# ESP32 register map
Vendor: ESPRESSIF SYSTEMS (SHANGHAI) CO., LTD.; Series: ESP32 Series; File version: 17
CPU: Xtensa LX6 r0p0, little endian, no MPU, FPU, 0 interrupt priority bits
Address unit: 32 bits
Registers are 32-bit, read-write, reset 0x0 unless marked. A register's access mark holds for its fields unless they carry their own. Offsets are from the block's base; [hi:lo] are bit positions; {n}, {i} and the like mark numbered series.

## UHCI0 — Universal Host Controller Interface 0
Base 0x3FF54000
Same registers: UHCI1 0x3FF4C000
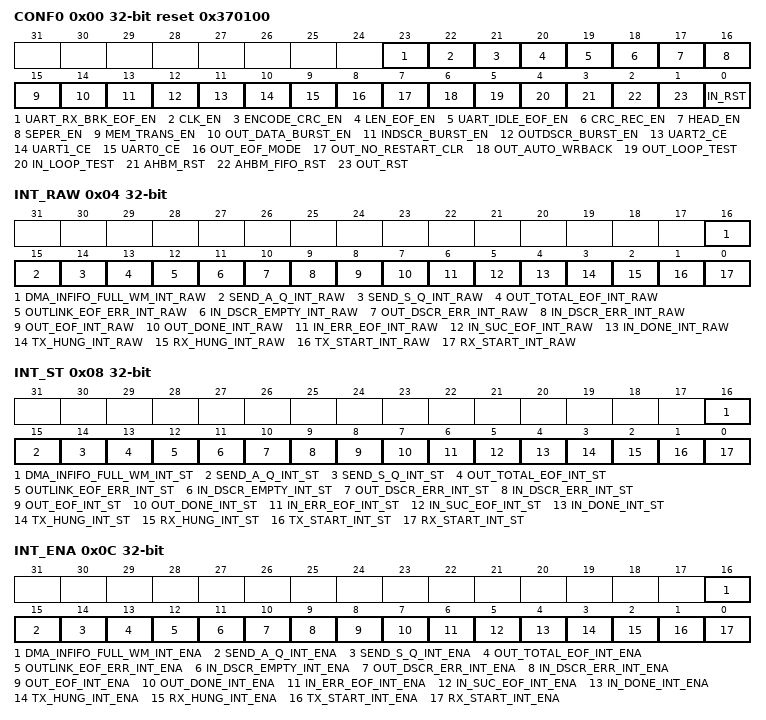
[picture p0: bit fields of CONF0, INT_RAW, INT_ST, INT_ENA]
0x00 CONF0 reset 0x370100
  [23] UART_RX_BRK_EOF_EN — Set this bit to enable to use brk char as the end of a data frame.
  [22] CLK_EN — Set this bit to enable clock-gating for read or write registers.
  [21] ENCODE_CRC_EN — Set this bit to enable crc calculation for data frame when bit6 in the head packet is 1.
  [20] LEN_EOF_EN — Set this bit to enable to use packet_len in packet head when the received data is equal to packet_len this means the end of a data frame.
  [19] UART_IDLE_EOF_EN — Set this bit to enable to use idle time when the idle time after data frame is satisfied this means the end of a data frame.
  [18] CRC_REC_EN — Set this bit to enable receiver''s ability of crc calculation when crc_en bit in head packet is 1 then there will be crc bytes after data_frame
  [17] HEAD_EN — Set this bit to enable to use head packet before the data frame.
  [16] SEPER_EN — Set this bit to use special char to separate the data frame.
  [15] MEM_TRANS_EN
  [14] OUT_DATA_BURST_EN — Set this bit to enable DMA burst MODE
  [13] INDSCR_BURST_EN — Set this bit to enable DMA out links to use burst mode.
  [12] OUTDSCR_BURST_EN — Set this bit to enable DMA in links to use burst mode.
  [11] UART2_CE — Set this bit to use UART2 to transmit or receive data.
  [10] UART1_CE — Set this bit to use UART1 to transmit or receive data.
  [9] UART0_CE — Set this bit to use UART to transmit or receive data.
  [8] OUT_EOF_MODE — Set this bit to produce eof after DMA pops all data clear this bit to produce eof after DMA pushes all data
  [7] OUT_NO_RESTART_CLR — don't use
  [6] OUT_AUTO_WRBACK — when in link's length is 0 go on to use the next in link automatically.
  [5] OUT_LOOP_TEST — Set this bit to enable loop test for out links.
  [4] IN_LOOP_TEST — Set this bit to enable loop test for in links.
  [3] AHBM_RST — Set this bit to reset dma ahb interface.
  [2] AHBM_FIFO_RST — Set this bit to reset dma ahb fifo.
  [1] OUT_RST — Set this bit to reset out link operations.
  [0] IN_RST — Set this bit to reset in link operations.
0x04 INT_RAW ro
  [16] DMA_INFIFO_FULL_WM_INT_RAW
  [15] SEND_A_Q_INT_RAW — When use always_send registers to send a series of short packets it will produce this interrupt when dma has send the short packet.
  [14] SEND_S_Q_INT_RAW — When use single send registers to send a short packets it will produce this interrupt when dma has send the short packet.
  [13] OUT_TOTAL_EOF_INT_RAW — When all data have been send it will produce uhci_out_total_eof_int interrupt.
  [12] OUTLINK_EOF_ERR_INT_RAW — when there are some errors about eof in outlink descriptor it will produce uhci_outlink_eof_err_int interrupt.
  [11] IN_DSCR_EMPTY_INT_RAW — when there are not enough in links for DMA it will produce uhci_in_dscr_err_int interrupt.
  [10] OUT_DSCR_ERR_INT_RAW — when there are some errors about the in link descriptor it will produce uhci_out_dscr_err_int interrupt.
  [9] IN_DSCR_ERR_INT_RAW — when there are some errors about the out link descriptor it will produce uhci_in_dscr_err_int interrupt.
  [8] OUT_EOF_INT_RAW — when the current descriptor's eof bit is 1 it will produce uhci_out_eof_int interrupt.
  [7] OUT_DONE_INT_RAW — when a out link descriptor is completed it will produce uhci_out_done_int interrupt.
  [6] IN_ERR_EOF_INT_RAW — when there are some errors about eof in in link descriptor it will produce uhci_in_err_eof_int interrupt.
  [5] IN_SUC_EOF_INT_RAW — when a data packet has been received it will produce uhci_in_suc_eof_int interrupt.
  [4] IN_DONE_INT_RAW — when a in link descriptor has been completed it will produce uhci_in_done_int interrupt.
  [3] TX_HUNG_INT_RAW — when DMA takes a lot of time to read a data from RAM it will produce uhci_tx_hung_int interrupt.
  [2] RX_HUNG_INT_RAW — when DMA takes a lot of time to receive a data it will produce uhci_rx_hung_int interrupt.
  [1] TX_START_INT_RAW — when DMA detects a separator char it will produce uhci_tx_start_int interrupt.
  [0] RX_START_INT_RAW — when a separator char has been send it will produce uhci_rx_start_int interrupt.
0x08 INT_ST ro
  [16] DMA_INFIFO_FULL_WM_INT_ST, [15] SEND_A_Q_INT_ST, [14] SEND_S_Q_INT_ST, [13] OUT_TOTAL_EOF_INT_ST, [12] OUTLINK_EOF_ERR_INT_ST, [11] IN_DSCR_EMPTY_INT_ST, [10] OUT_DSCR_ERR_INT_ST, [9] IN_DSCR_ERR_INT_ST, [8] OUT_EOF_INT_ST, [7] OUT_DONE_INT_ST, [6] IN_ERR_EOF_INT_ST, [5] IN_SUC_EOF_INT_ST, [4] IN_DONE_INT_ST, [3] TX_HUNG_INT_ST, [2] RX_HUNG_INT_ST, [1] TX_START_INT_ST, [0] RX_START_INT_ST
0x0C INT_ENA
  [16] DMA_INFIFO_FULL_WM_INT_ENA, [15] SEND_A_Q_INT_ENA, [14] SEND_S_Q_INT_ENA, [13] OUT_TOTAL_EOF_INT_ENA, [12] OUTLINK_EOF_ERR_INT_ENA, [11] IN_DSCR_EMPTY_INT_ENA, [10] OUT_DSCR_ERR_INT_ENA, [9] IN_DSCR_ERR_INT_ENA, [8] OUT_EOF_INT_ENA, [7] OUT_DONE_INT_ENA, [6] IN_ERR_EOF_INT_ENA, [5] IN_SUC_EOF_INT_ENA, [4] IN_DONE_INT_ENA, [3] TX_HUNG_INT_ENA, [2] RX_HUNG_INT_ENA, [1] TX_START_INT_ENA, [0] RX_START_INT_ENA
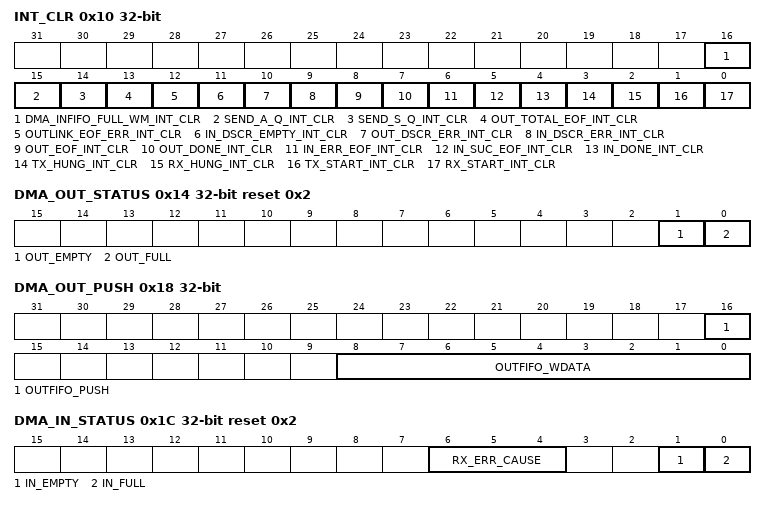
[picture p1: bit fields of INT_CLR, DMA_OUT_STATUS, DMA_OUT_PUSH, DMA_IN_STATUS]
0x10 INT_CLR wo
  [16] DMA_INFIFO_FULL_WM_INT_CLR, [15] SEND_A_Q_INT_CLR, [14] SEND_S_Q_INT_CLR, [13] OUT_TOTAL_EOF_INT_CLR, [12] OUTLINK_EOF_ERR_INT_CLR, [11] IN_DSCR_EMPTY_INT_CLR, [10] OUT_DSCR_ERR_INT_CLR, [9] IN_DSCR_ERR_INT_CLR, [8] OUT_EOF_INT_CLR, [7] OUT_DONE_INT_CLR, [6] IN_ERR_EOF_INT_CLR, [5] IN_SUC_EOF_INT_CLR, [4] IN_DONE_INT_CLR, [3] TX_HUNG_INT_CLR, [2] RX_HUNG_INT_CLR, [1] TX_START_INT_CLR, [0] RX_START_INT_CLR
0x14 DMA_OUT_STATUS ro reset 0x2
  [1] OUT_EMPTY — 1:DMA in link descriptor's fifo is empty.
  [0] OUT_FULL — 1:DMA out link descriptor's fifo is full.
0x18 DMA_OUT_PUSH
  [16] OUTFIFO_PUSH — Set this bit to push data in out link descriptor's fifo.
  [8:0] OUTFIFO_WDATA — This is the data need to be pushed into out link descriptor's fifo.
0x1C DMA_IN_STATUS ro reset 0x2
  [6:4] RX_ERR_CAUSE — This register stores the errors caused in out link descriptor's data packet.
  [1] IN_EMPTY
  [0] IN_FULL
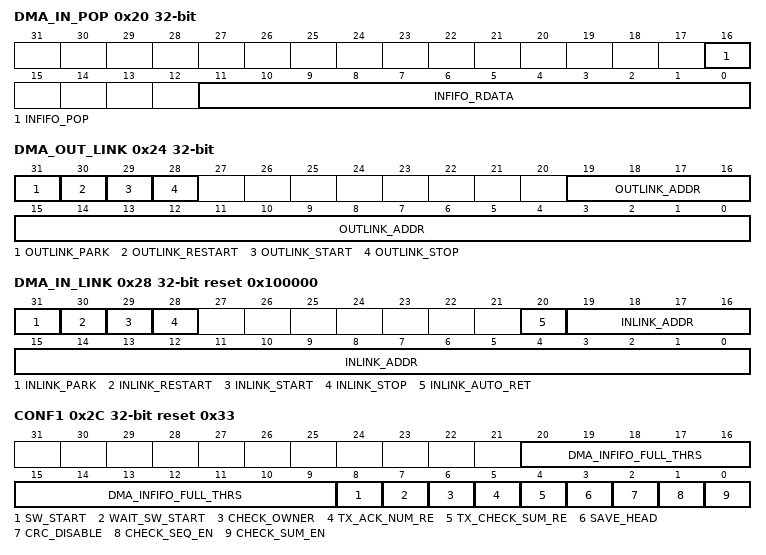
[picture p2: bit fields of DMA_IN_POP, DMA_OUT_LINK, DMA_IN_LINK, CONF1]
0x20 DMA_IN_POP access per field
  [16] INFIFO_POP rw — Set this bit to pop data in in link descriptor's fifo.
  [11:0] INFIFO_RDATA ro — This register stores the data pop from in link descriptor's fifo.
0x24 DMA_OUT_LINK access per field
  [31] OUTLINK_PARK ro — 1£º the out link descriptor's fsm is in idle state. 0:the out link descriptor's fsm is working.
  [30] OUTLINK_RESTART rw — Set this bit to mount on new out link descriptors
  [29] OUTLINK_START rw — Set this bit to start dealing with the out link descriptors.
  [28] OUTLINK_STOP rw — Set this bit to stop dealing with the out link descriptors.
  [19:0] OUTLINK_ADDR rw — This register stores the least 20 bits of the first out link descriptor's address.
0x28 DMA_IN_LINK access per field reset 0x100000
  [31] INLINK_PARK ro — 1:the in link descriptor's fsm is in idle state. 0:the in link descriptor's fsm is working
  [30] INLINK_RESTART rw — Set this bit to mount on new in link descriptors
  [29] INLINK_START rw — Set this bit to start dealing with the in link descriptors.
  [28] INLINK_STOP rw — Set this bit to stop dealing with the in link descriptors.
  [20] INLINK_AUTO_RET rw — 1:when a packet is wrong in link descriptor returns to the descriptor which is lately used.
  [19:0] INLINK_ADDR rw — This register stores the least 20 bits of the first in link descriptor's address.
0x2C CONF1 reset 0x33
  [20:9] DMA_INFIFO_FULL_THRS — when data amount in link descriptor's fifo is more than this register value it will produce uhci_dma_infifo_full_wm_int interrupt.
  [8] SW_START — Set this bit to start inserting the packet header.
  [7] WAIT_SW_START — Set this bit to enable software way to add packet header.
  [6] CHECK_OWNER — Set this bit to check the owner bit in link descriptor.
  [5] TX_ACK_NUM_RE — Set this bit to enable hardware replace ack num in packet header automatically.
  [4] TX_CHECK_SUM_RE — Set this bit to enable hardware replace check_sum in packet header automatically.
  [3] SAVE_HEAD — Set this bit to save packet header .
  [2] CRC_DISABLE — Set this bit to disable crc calculation.
  [1] CHECK_SEQ_EN — Set this bit to enable decoder to check seq num in packet header.
  [0] CHECK_SUM_EN — Set this bit to enable decoder to check check_sum in packet header.
0x30 STATE0 ro
0x34 STATE1 ro
0x38 DMA_OUT_EOF_DES_ADDR ro
  [31:0] OUT_EOF_DES_ADDR — This register stores the address of out link descriptoir when eof bit in this descriptor is 1.
0x3C DMA_IN_SUC_EOF_DES_ADDR ro
  [31:0] IN_SUC_EOF_DES_ADDR — This register stores the address of in link descriptor when eof bit in this descriptor is 1.
0x40 DMA_IN_ERR_EOF_DES_ADDR ro
  [31:0] IN_ERR_EOF_DES_ADDR — This register stores the address of in link descriptor when there are some errors in this descriptor.
0x44 DMA_OUT_EOF_BFR_DES_ADDR ro
  [31:0] OUT_EOF_BFR_DES_ADDR — This register stores the address of out link descriptor when there are some errors in this descriptor.
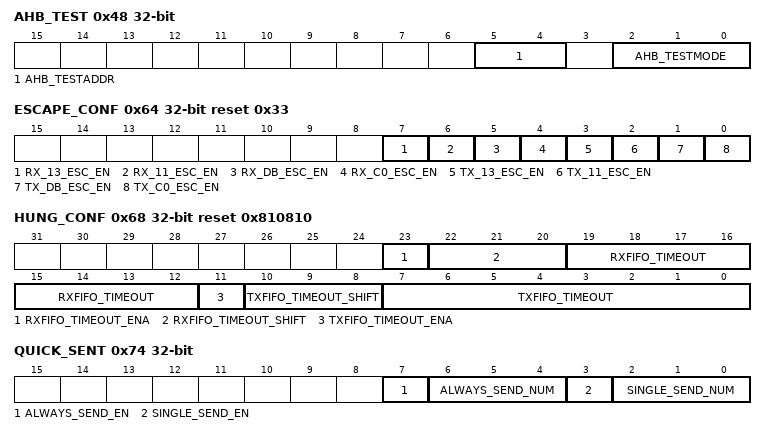
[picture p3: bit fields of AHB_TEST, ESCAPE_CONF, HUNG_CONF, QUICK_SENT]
0x48 AHB_TEST
  [5:4] AHB_TESTADDR — The two bits represent ahb bus address bit[20:19]
  [2:0] AHB_TESTMODE — bit2 is ahb bus test enable ,bit1 is used to choose wrtie(1) or read(0) mode. bit0 is used to choose test only once(1) or continue(0)
0x4C DMA_IN_DSCR ro
  [31:0] INLINK_DSCR — The content of current in link descriptor's third dword
0x50 DMA_IN_DSCR_BF0 ro
  [31:0] INLINK_DSCR_BF0 — The content of current in link descriptor's first dword
0x54 DMA_IN_DSCR_BF1 ro
  [31:0] INLINK_DSCR_BF1 — The content of current in link descriptor's second dword
0x58 DMA_OUT_DSCR ro
  [31:0] OUTLINK_DSCR — The content of current out link descriptor's third dword
0x5C DMA_OUT_DSCR_BF0 ro
  [31:0] OUTLINK_DSCR_BF0 — The content of current out link descriptor's first dword
0x60 DMA_OUT_DSCR_BF1 ro
  [31:0] OUTLINK_DSCR_BF1 — The content of current out link descriptor's second dword
0x64 ESCAPE_CONF reset 0x33
  [7] RX_13_ESC_EN — Set this bit to enable flow control char 0x13 replace when DMA sends data.
  [6] RX_11_ESC_EN — Set this bit to enable flow control char 0x11 replace when DMA sends data.
  [5] RX_DB_ESC_EN — Set this bit to enable 0xdb char replace when DMA sends data.
  [4] RX_C0_ESC_EN — Set this bit to enable 0xc0 char replace when DMA sends data.
  [3] TX_13_ESC_EN — Set this bit to enable flow control char 0x13 decode when DMA receives data.
  [2] TX_11_ESC_EN — Set this bit to enable flow control char 0x11 decode when DMA receives data.
  [1] TX_DB_ESC_EN — Set this bit to enable 0xdb char decode when DMA receives data.
  [0] TX_C0_ESC_EN — Set this bit to enable 0xc0 char decode when DMA receives data.
0x68 HUNG_CONF reset 0x810810
  [23] RXFIFO_TIMEOUT_ENA — This is the enable bit for DMA send data timeout
  [22:20] RXFIFO_TIMEOUT_SHIFT — The tick count is cleared when its value >=(17'd8000>>reg_rxfifo_timeout_shift)
  [19:12] RXFIFO_TIMEOUT — This register stores the timeout value.when DMA takes more time than this register value to read a data from RAM it will produce uhci_rx_hung_int interrupt.
  [11] TXFIFO_TIMEOUT_ENA — The enable bit for txfifo receive data timeout
  [10:8] TXFIFO_TIMEOUT_SHIFT — The tick count is cleared when its value >=(17'd8000>>reg_txfifo_timeout_shift)
  [7:0] TXFIFO_TIMEOUT — This register stores the timeout value.when DMA takes more time than this register value to receive a data it will produce uhci_tx_hung_int interrupt.
0x6C ACK_NUM access not given
0x70 RX_HEAD ro
  [31:0] RX_HEAD — This register stores the packet header received by DMA
0x74 QUICK_SENT
  [7] ALWAYS_SEND_EN — Set this bit to enable continuously send the same short packet
  [6:4] ALWAYS_SEND_NUM — The bits are used to choose which short packet
  [3] SINGLE_SEND_EN — Set this bit to enable send a short packet
  [2:0] SINGLE_SEND_NUM — The bits are used to choose which short packet
{0x78+8i} Q{i}_WORD0 (i=0..6)
  [31:0] SEND_Q{i}_WORD0 — This register stores the content of short packet's first dword
{0x7C+8i} Q{i}_WORD1 (i=0..6)
  [31:0] SEND_Q{i}_WORD1 — This register stores the content of short packet's second dword
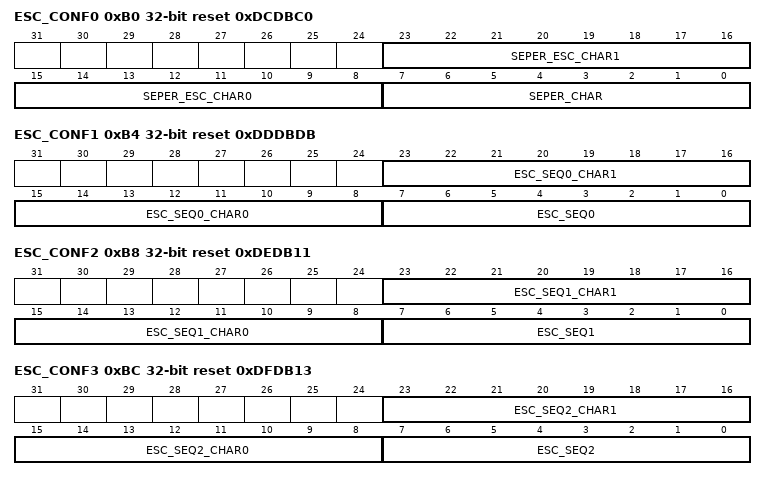
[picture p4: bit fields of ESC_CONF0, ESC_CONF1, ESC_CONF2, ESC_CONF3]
0xB0 ESC_CONF0 reset 0xDCDBC0
  [23:16] SEPER_ESC_CHAR1 — This register stores the second char used to replace seperator char in data . 0xdc 0xdb replace 0xc0 by default.
  [15:8] SEPER_ESC_CHAR0 — This register stores thee first char used to replace seperator char in data.
  [7:0] SEPER_CHAR — This register stores the seperator char seperator char is used to seperate the data frame.
0xB4 ESC_CONF1 reset 0xDDDBDB
  [23:16] ESC_SEQ0_CHAR1 — This register stores the second char used to replace the reg_esc_seq0 in data
  [15:8] ESC_SEQ0_CHAR0 — This register stores the first char used to replace reg_esc_seq0 in data.
  [7:0] ESC_SEQ0 — This register stores the first substitute char used to replace the seperator char.
0xB8 ESC_CONF2 reset 0xDEDB11
  [23:16] ESC_SEQ1_CHAR1 — This register stores the second char used to replace the reg_esc_seq1 in data.
  [15:8] ESC_SEQ1_CHAR0 — This register stores the first char used to replace the reg_esc_seq1 in data.
  [7:0] ESC_SEQ1 — This register stores the flow control char to turn on the flow_control
0xBC ESC_CONF3 reset 0xDFDB13
  [23:16] ESC_SEQ2_CHAR1 — This register stores the second char used to replace the reg_esc_seq2 in data.
  [15:8] ESC_SEQ2_CHAR0 — This register stores the first char used to replace the reg_esc_seq2 in data.
  [7:0] ESC_SEQ2 — This register stores the flow_control char to turn off the flow_control
0xC0 PKT_THRES reset 0x80
  [12:0] PKT_THRS — when the amount of packet payload is greater than this value the process of receiving data is done.
0xFC DATE reset 0x16041001
  [31:0] DATE — version information
